# ATSAMG51G18 register map
Vendor: Microchip Technology; Series: SAMG51; File version: 0
CPU: CM4 r0p1, little endian, MPU, FPU, 4 interrupt priority bits, 30 interrupts
Registers are 32-bit, read-write, reset 0x0 unless marked. A register's access mark holds for its fields unless they carry their own. Offsets are from the block's base; [hi:lo] are bit positions; 'fields as' and 'values as' point back to an identical list.

## MEM2MEM — Memory to Memory
Base 0x40028000
0x00 THR — Memory to Memory Transfer Holding Register
  [31:0] THDATA — Transfer Holding Data
0x04 MR — Memory to Memory Mode Register
  [1:0] TSIZE — Transfer Size
    0=T_8BIT (The buffer size is defined in byte.); 1=T_16BIT (The buffer size is defined in half-word (16-bit).); 2=T_32BIT (The buffer size is defined in word (32-bit). Default value.)
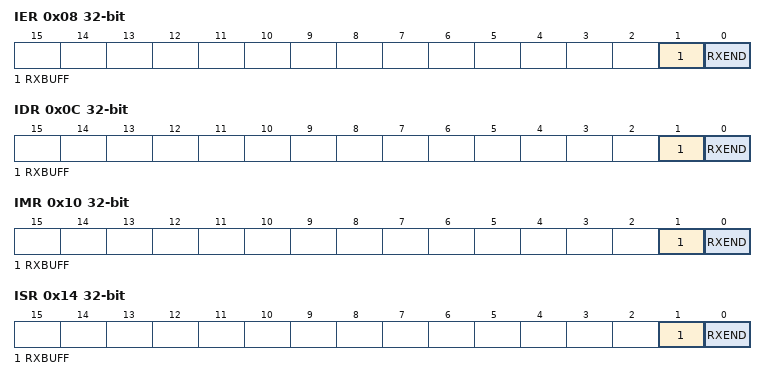
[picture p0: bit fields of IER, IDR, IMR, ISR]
0x08 IER wo — Memory to Memory Interrupt Enable Register
  [1] RXBUFF — Buffer Full Interrupt Enable
  [0] RXEND — End of Transfer Interrupt Enable
0x0C IDR wo — Memory to Memory Interrupt Disable Register
  [1] RXBUFF — Buffer Full Interrupt Disable
  [0] RXEND — End of Transfer Interrupt Disable
0x10 IMR ro — Memory to Memory Interrupt Mask Register
  [1] RXBUFF — Buffer Full Interrupt Mask
  [0] RXEND — End of Transfer Interrupt Mask
0x14 ISR ro — Memory to Memory Interrupt Status Register
  [1] RXBUFF — Buffer Full
  [0] RXEND — End of Transfer
0x100 RPR — Receive Pointer Register
  [31:0] RXPTR
0x104 RCR — Receive Counter Register
  [15:0] RXCTR
0x108 TPR — Transmit Pointer Register
  [31:0] TXPTR — Transmit Counter Register
0x10C TCR — Transmit Counter Register
  [15:0] TXCTR
0x110 RNPR — Receive Next Pointer Register
  [31:0] RXNPTR — Receive Next Pointer
0x114 RNCR — Receive Next Counter Register
  [15:0] RXNCTR — Receive Next Counter
0x118 TNPR — Transmit Next Pointer Register
  [31:0] TXNPTR — Transmit Next Pointer
0x11C TNCR — Transmit Next Counter Register
  [15:0] TXNCTR — Transmit Counter Next
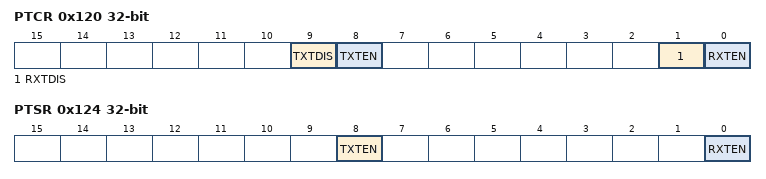
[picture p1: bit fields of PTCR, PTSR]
0x120 PTCR wo — Transfer Control Register
  [9] TXTDIS — Transmitter Transfer Disable
  [8] TXTEN — Transmitter Transfer Enable
  [1] RXTDIS — Receiver Transfer Disable
  [0] RXTEN — Receiver Transfer Enable
0x124 PTSR ro — Transfer Status Register
  [8] TXTEN — Transmitter Transfer Enable
  [0] RXTEN — Receiver Transfer Enable

## RSTC — Reset Controller
Base 0x400E1400
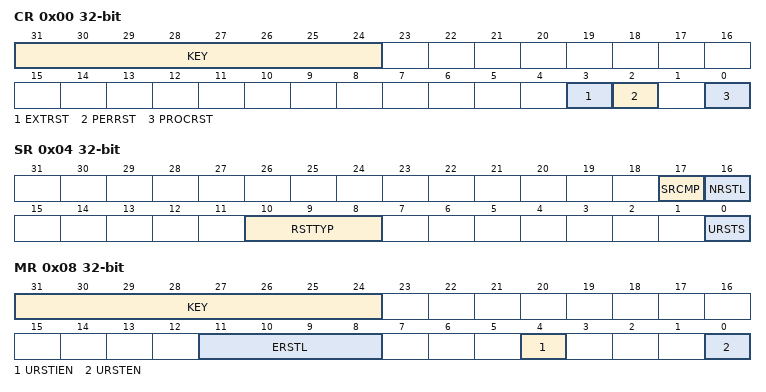
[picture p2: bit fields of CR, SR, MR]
0x00 CR wo — Control Register
  [31:24] KEY — System Reset Key
    165=PASSWD (Writing any other value in this field aborts the write operation.)
  [3] EXTRST — External Reset
  [2] PERRST — Peripheral Reset
  [0] PROCRST — Processor Reset
0x04 SR ro — Status Register
  [17] SRCMP — Software Reset Command in Progress
  [16] NRSTL — NRST Pin Level
  [10:8] RSTTYP — Reset Type
    0=GENERAL_RST (First power-up reset); 2=WDT_RST (Watchdog fault occurred); 3=SOFT_RST (Processor reset required by the software); 4=USER_RST (NRST pin detected low)
  [0] URSTS — User Reset Status
0x08 MR — Mode Register
  [31:24] KEY — Write Access Password
    165=PASSWD (Writing any other value in this field aborts the write operation.Always reads as 0.)
  [11:8] ERSTL — External Reset Length
  [4] URSTIEN — User Reset Interrupt Enable
  [0] URSTEN — User Reset Enable

## RTT — Real-time Timer
Base 0x400E1430
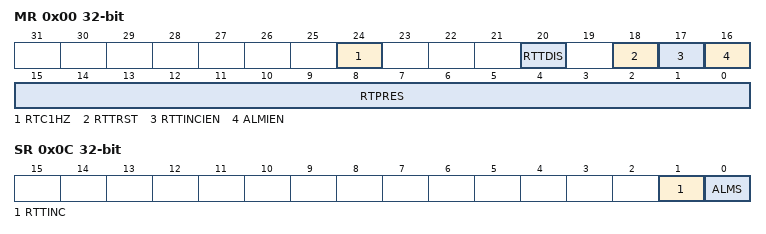
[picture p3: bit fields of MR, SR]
0x00 MR — Mode Register
  [24] RTC1HZ — Real-Time Clock 1Hz Clock Selection
  [20] RTTDIS — Real-time Timer Disable
  [18] RTTRST — Real-time Timer Restart
  [17] RTTINCIEN — Real-time Timer Increment Interrupt Enable
  [16] ALMIEN — Alarm Interrupt Enable
  [15:0] RTPRES — Real-time Timer Prescaler Value
0x04 AR — Alarm Register
  [31:0] ALMV — Alarm Value
0x08 VR ro — Value Register
  [31:0] CRTV — Current Real-time Value
0x0C SR ro — Status Register
  [1] RTTINC — Prescaler Roll-over Status (cleared on read)
  [0] ALMS — Real-time Alarm Status (cleared on read)

## SUPC — Supply Controller
Base 0x400E1410
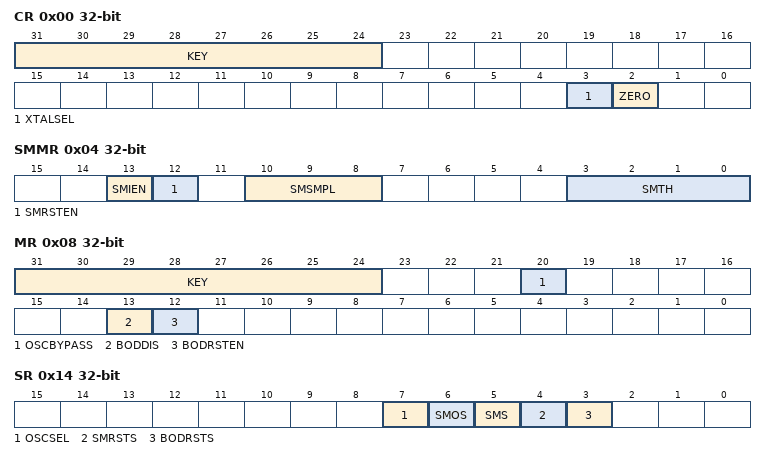
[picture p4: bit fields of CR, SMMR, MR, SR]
0x00 CR wo — Supply Controller Control Register
  [31:24] KEY — Password
    165=PASSWD (Writing any other value in this field aborts the write operation.Always reads as 0.)
  [3] XTALSEL — Crystal Oscillator Select
    0=NO_EFFECT; 1=CRYSTAL_SEL (If KEY is correct, switches the slow clock on the crystal oscillator output.)
  [2] ZERO — This bit must always be written to 0.
0x04 SMMR — Supply Controller Supply Monitor Mode Register
  [13] SMIEN — Supply Monitor Interrupt Enable
    0=NOT_ENABLE (The SUPC interrupt signal is not affected when a supply monitor detection occurs.); 1=ENABLE (The SUPC interrupt signal is asserted when a supply monitor detection occurs.)
  [12] SMRSTEN — Supply Monitor Reset Enable
    0=NOT_ENABLE (The core reset signal vddcore_nreset is not affected when a supply monitor detection occurs.); 1=ENABLE (The core reset signal vddcore_nreset is asserted when a supply monitor detection occurs.)
  [10:8] SMSMPL — Supply Monitor Sampling Period
    0=SMD (Supply Monitor disabled); 1=CSM (Continuous Supply Monitor); 2=_32SLCK (Supply Monitor enables one SLCK period every 32 SLCK periods); 3=_256SLCK (Supply Monitor enables one SLCK period every 256 SLCK periods); 4=_2048SLCK (Supply Monitor enables one SLCK period every 2,048 SLCK periods)
  [3:0] SMTH — Supply Monitor Threshold
    1=V1P72 (1.72 V); 2=V1P84 (1.84 V); 3=V1P96 (1.96 V)
0x08 MR — Supply Controller Mode Register
  [31:24] KEY — Password Key
    values as CR.KEY
  [20] OSCBYPASS — Oscillator Bypass
    0=NO_EFFECT (No effect. Clock selection depends on XTALSEL value.); 1=BYPASS (The 32 kHz crystal oscillator is bypassed if XTALSEL=1. OSCBYPASS must be set prior to write XTALSEL=1.)
  [13] BODDIS — POR Core Disable
    0=ENABLE (The core brownout detector is enabled.); 1=DISABLE (The core brownout detector is disabled.)
  [12] BODRSTEN — POR Core Reset Enable
    0=NOT_ENABLE (The core reset signal vddcore_nreset is not affected when a brownout detection occurs.); 1=ENABLE (The core reset signal vddcore_nreset is asserted when a brownout detection occurs.)
0x14 SR ro — Supply Controller Status Register
  [7] OSCSEL — 32-kHz Oscillator Selection Status
    0=RC (The slow clock SLCK is generated by the embedded 32 kHz RC oscillator.); 1=CRYST (The slow clock SLCK is generated by the 32 kHz crystal oscillator.)
  [6] SMOS — Supply Monitor Output Status
    0=HIGH (The supply monitor detected VDDIO higher than its threshold at its last measurement.); 1=LOW (The supply monitor detected VDDIO lower than its threshold at its last measurement.)
  [5] SMS — Supply Monitor Status (cleared on read)
    0=NO (No supply monitor detection since the last read of SUPC_SR.); 1=PRESENT (At least one supply monitor detection since the last read of SUPC_SR.)
  [4] SMRSTS — Supply Monitor Reset Status (cleared on read)
    0=NO (No supply monitor detection has generated a core reset since the last read of SUPC_SR.); 1=PRESENT (At least one supply monitor detection has generated a core reset since the last read of SUPC_SR.)
  [3] BODRSTS — Brownout Detector Reset Status (cleared on read)
    0=NO (No core brownout rising edge event has been detected since the last read of SUPC_SR.); 1=PRESENT (At least one brownout output rising edge event has been detected since the last read of SUPC_SR.)

## Notices in the file
Copyright (c) 2026 Microchip Technology Inc.
SPDX-License-Identifier: Apache-2.0
Licensed under the Apache License, Version 2.0 (the "License");
you may not use this file except in compliance with the License.
You may obtain a copy of the License at
http://www.apache.org/licenses/LICENSE-2.0
Unless required by applicable law or agreed to in writing, software
distributed under the License is distributed on an "AS IS" BASIS,
WITHOUT WARRANTIES OR CONDITIONS OF ANY KIND, either express or implied.
See the License for the specific language governing permissions and
limitations under the License.
